AUTOSAR XML (schema 00052)
package /adcm/AdaptiveApplicationSwComponentTypes
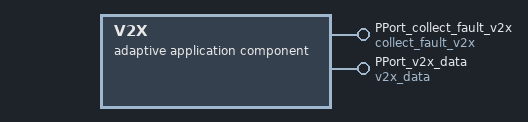
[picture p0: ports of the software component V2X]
  adaptive application sw component type V2X
    provide port PPort_collect_fault_v2x: provided-interface=collect_fault_v2x
    provide port PPort_v2x_data: provided-interface=v2x_data
package /adcm/Executables
  executable V2X: category=APPLICATION_LEVEL, minimum-timer-granularity=1000
    root sw component prototype V2X: application-type=V2X
